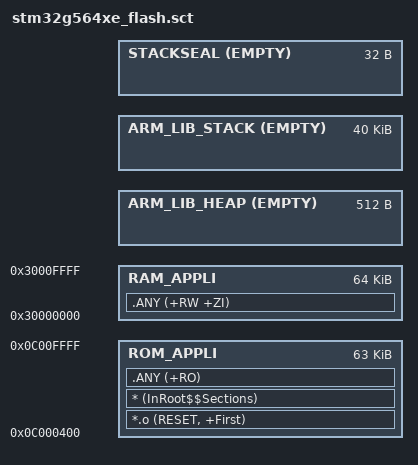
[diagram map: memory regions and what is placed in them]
#! armclang -E --target=arm-arm-none-eabi -mcpu=cortex-m33 -xc
; command above MUST be in first line (no comment above!)

; ******************************************************************************
; * @file    stm32g564xe_flash.sct
; * @brief   Linker File
; ******************************************************************************
; * @attention
; *
; * Copyright (c) 2026 STMicroelectronics.
; * All rights reserved.
; *
; * This software is licensed under terms that can be found in the LICENSE file
; * in the root directory of this software component.
; * If no LICENSE file comes with this software, it is provided AS-IS.
; *
; ******************************************************************************

/* Do not edit ROM_APPLI_xxxxxx definitions, updated by the provisioning scripts */
#define ROM_APPLI_ADDRESS   0xC000400
#define ROM_APPLI_SIZE      0xFC00

#define RAM_APPLI_ADDRESS   0x30000000
#define RAM_APPLI_SIZE      0x10000

#define __HEAP_SIZE         0x200
#define __STACK_SIZE        0xA000


ROM_APPLI ROM_APPLI_ADDRESS
{
  ROM_APPLI ROM_APPLI_ADDRESS ROM_APPLI_SIZE
  {
    *.o (RESET, +First)
    * (InRoot$$Sections)
    .ANY (+RO)
  }

  RAM_APPLI RAM_APPLI_ADDRESS RAM_APPLI_SIZE
  {
    .ANY (+RW +ZI)
  }

  ARM_LIB_HEAP AlignExpr(+0, 8) EMPTY  __HEAP_SIZE
  {
  }

  ARM_LIB_STACK AlignExpr(+0, 8) EMPTY  __STACK_SIZE
  {
  }
  /* STACK SEAL region for Cortex-M33 stack protection
   * Needed because startup_stm32g564xx.o references Image$$STACKSEAL$$ZI$$Base
   */
  STACKSEAL AlignExpr(+0, 8) EMPTY 0x20
  {
  }
}
